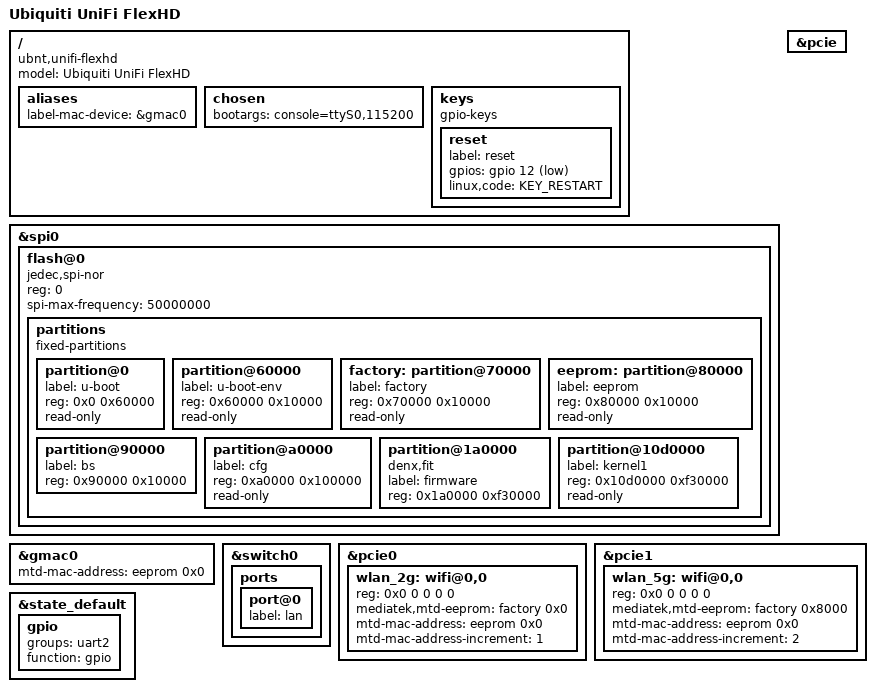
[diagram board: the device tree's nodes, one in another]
// SPDX-License-Identifier: GPL-2.0-or-later OR MIT

#include "mt7621.dtsi"

#include <dt-bindings/gpio/gpio.h>
#include <dt-bindings/input/input.h>

/ {
	compatible = "ubnt,unifi-flexhd", "mediatek,mt7621-soc";
	model = "Ubiquiti UniFi FlexHD";

	aliases {
		label-mac-device = &gmac0;
	};

	chosen {
		bootargs = "console=ttyS0,115200";
	};

	keys {
		compatible = "gpio-keys";

		reset {
			label = "reset";
			gpios = <&gpio 12 GPIO_ACTIVE_LOW>;
			linux,code = <KEY_RESTART>;
		};
	};
};

&spi0 {
	status = "okay";

	flash@0 {
		compatible = "jedec,spi-nor";
		reg = <0>;
		spi-max-frequency = <50000000>;

		partitions {
			compatible = "fixed-partitions";
			#address-cells = <1>;
			#size-cells = <1>;

			partition@0 {
				label = "u-boot";
				reg = <0x0 0x60000>;
				read-only;
			};

			partition@60000 {
				label = "u-boot-env";
				reg = <0x60000 0x10000>;
				read-only;
			};

			factory: partition@70000 {
				label = "factory";
				reg = <0x70000 0x10000>;
				read-only;
			};

			eeprom: partition@80000 {
				label = "eeprom";
				reg = <0x80000 0x10000>;
				read-only;
			};

			partition@90000 {
				label = "bs";
				reg = <0x90000 0x10000>;
			};

			partition@a0000 {
				label = "cfg";
				reg = <0xa0000 0x100000>;
				read-only;
			};

			partition@1a0000 {
				compatible = "denx,fit";
				label = "firmware";
				reg = <0x1a0000 0xf30000>;
			};

			partition@10d0000 {
				label = "kernel1";
				reg = <0x10d0000 0xf30000>;
				read-only;
			};
		};
	};
};

&gmac0 {
	mtd-mac-address = <&eeprom 0x0>;
};

&switch0 {
	ports {
		port@0 {
			status = "okay";
			label = "lan";
		};
	};
};

&pcie {
	status = "okay";
};

&pcie0 {
	wlan_2g: wifi@0,0 {
		reg = <0x0 0 0 0 0>;
		mediatek,mtd-eeprom = <&factory 0x0>;
	};
};

&pcie1 {
	wlan_5g: wifi@0,0 {
		reg = <0x0 0 0 0 0>;
	};
};

&wlan_2g {
	mtd-mac-address = <&eeprom 0x0>;
	mtd-mac-address-increment = <1>;
};

&wlan_5g {
	mediatek,mtd-eeprom = <&factory 0x8000>;
	mtd-mac-address = <&eeprom 0x0>;
	mtd-mac-address-increment = <2>;
};

&state_default {
	gpio {
		groups = "uart2";
		function = "gpio";
	};
};
